# GD32E50x_CL register map
File version: 1.0
CPU: CM33 r0p4, little endian, MPU, FPU, 4 interrupt priority bits
Registers are 32-bit, read-write, reset 0x0 unless marked. A register's access mark holds for its fields unless they carry their own. Offsets are from the block's base; [hi:lo] are bit positions; {n}, {i} and the like mark numbered series; 'fields as' and 'values as' point back to an identical list.

## USBGS_HOST — USB on the go high speed host
Base 0x50000400
0x00 HCTL — host configuration register (HCTL)
  [2] SPDFSLS — Speed limited to FS and LS
0x04 HFT reset 0xBB80 — Host frame interval register
  [15:0] FRI — Frame interval
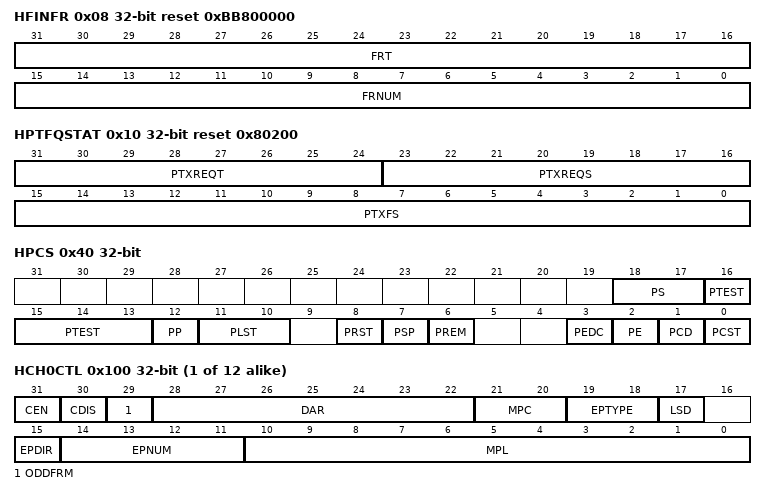
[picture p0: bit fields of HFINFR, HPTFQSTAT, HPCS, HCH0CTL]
0x08 HFINFR ro reset 0xBB800000 — OTG_FS host frame number/frame time remaining register (HFINFR)
  [31:16] FRT — Frame remaining time
  [15:0] FRNUM — Frame number
0x10 HPTFQSTAT ro reset 0x80200 — Host periodic transmit FIFO/queue status register (HPTFQSTAT)
  [31:24] PTXREQT — Top of the periodic transmit request queue
  [23:16] PTXREQS — Periodic transmit request queue space available
  [15:0] PTXFS — Periodic transmit data FIFO space available
0x14 HACHINT ro — Host all channels interrupt register
  [11:0] HACHINT — Host all channel interrupts
0x18 HACHINTEN — host all channels interrupt mask register
  [11:0] CINTEN — Channel interrupt enable
0x40 HPCS access per field — Host port control and status register (USBFS_HPCS)
  [18:17] PS ro — Port speed
  [16:13] PTEST rw — Port Test control
  [12] PP rw — Port power
  [11:10] PLST ro — Port line status
  [8] PRST rw — Port reset
  [7] PSP rw — Port suspend
  [6] PREM rw — Port resume
  [3] PEDC rw — Port enable/disable change
  [2] PE rw — Port enable
  [1] PCD rw — Port connect detected
  [0] PCST ro — Port connect status
{0x100+0x20*i} HCH{i}CTL (i=0..11) — host channel-{i} characteristics register (HCH{i}CTL)
  [31] CEN — Channel enable
  [30] CDIS — Channel disable
  [29] ODDFRM — Odd frame
  [28:22] DAR — Device address
  [21:20] MPC — Multiple Packet Count
  [19:18] EPTYPE — Endpoint type
  [17] LSD — Low-speed device
  [15] EPDIR — Endpoint direction
  [14:11] EPNUM — Endpoint number
  [10:0] MPL — Maximum packet size
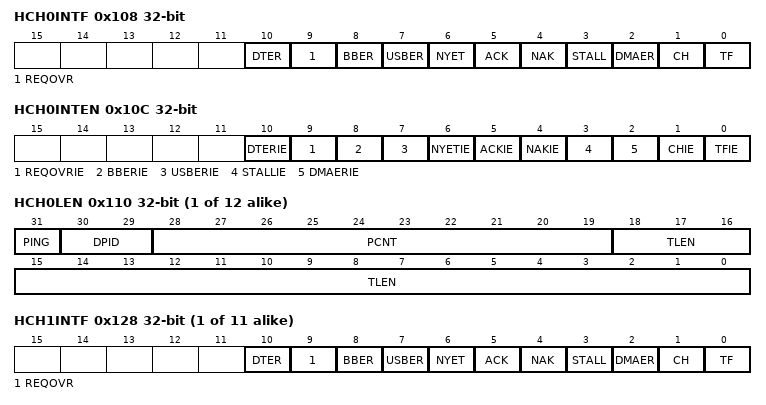
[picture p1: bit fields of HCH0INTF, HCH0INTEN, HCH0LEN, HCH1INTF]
0x108 HCH0INTF — host channel-0 interrupt register (USBHS_HCHxINTF)
  [10] DTER — Data toggle error
  [9] REQOVR — Request queue overrun
  [8] BBER — Babble error
  [7] USBER — USB bus error
  [6] NYET
  [5] ACK — ACK response received/transmitted interrupt
  [4] NAK — NAK response received interrupt
  [3] STALL — STALL response received interrupt
  [2] DMAER — DMA Error
  [1] CH — Channel halted
  [0] TF — Transfer finished
0x10C HCH0INTEN — host channel-0 interrupt enable register (HCH0INTEN)
  [10] DTERIE — Data toggle error interrupt enable
  [9] REQOVRIE — request queue overrun interrupt enable
  [8] BBERIE — Babble error interrupt enable
  [7] USBERIE — USB bus error interrupt enable
  [6] NYETIE — NYET interrupt enable
  [5] ACKIE — ACK interrupt enable
  [4] NAKIE — NAK interrupt enable
  [3] STALLIE — STALL interrupt enable
  [2] DMAERIE — DMA Error interrupt enable
  [1] CHIE — Channel halted interrupt enable
  [0] TFIE — Transfer completed interrupt enable
{0x110+0x20*i} HCH{i}LEN (i=0..11) — host channel-{i} transfer length register
  [31] PING — PING token request
  [30:29] DPID — Data PID
  [28:19] PCNT — Packet count
  [18:0] TLEN — Transfer length
{0x114+0x20*i} HCH{i}DMAADDR (i=0..11) — Host channel {i} DMA address register
  [31:0] DMAADDR — DMA address
{0x108+0x20*i} HCH{i}INTF (i=1..11) — host channel-{i} interrupt register (HCH{i}INTF)
  fields as HCH0INTF
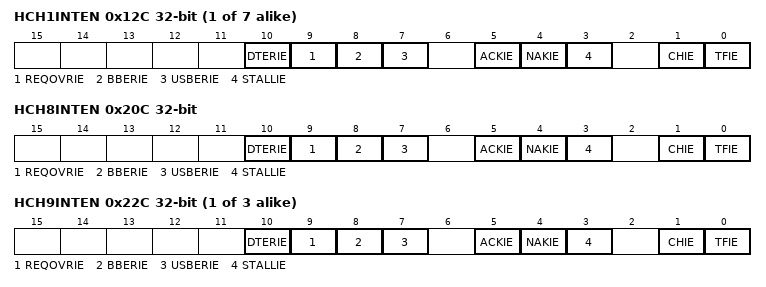
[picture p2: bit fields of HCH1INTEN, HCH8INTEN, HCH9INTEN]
{0x10C+0x20*i} HCH{i}INTEN (i=1..7) — host channel-{i} interrupt enable register (HCH{i}INTEN)
  [10] DTERIE — Data toggle error interrupt enable
  [9] REQOVRIE — request queue overrun interrupt enable
  [8] BBERIE — Babble error interrupt enable
  [7] USBERIE — USB bus error interrupt enable
  [5] ACKIE — ACK interrupt enable
  [4] NAKIE — NAK interrupt enable
  [3] STALLIE — STALL interrupt enable
  [1] CHIE — Channel halted interrupt enable
  [0] TFIE — Transfer completed interrupt enable
0x20C HCH8INTEN — host channel-8 interrupt enable register (HCH7INTEN)
  fields as HCH1INTEN
{0x10C+0x20*i} HCH{i}INTEN (i=9..11) — host channel-{i} interrupt enable register (HCH{i}INTEN)
  fields as HCH1INTEN
